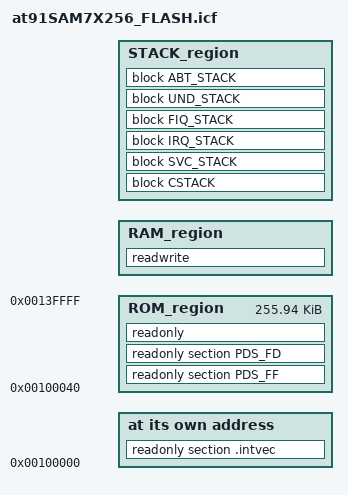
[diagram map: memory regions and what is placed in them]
/*###ICF### Section handled by ICF editor, don't touch! ****/

/*-Sizes-*/
define symbol __ICFEDIT_size_cstack__   = 0x400;
define symbol __ICFEDIT_size_svcstack__ = 0x400;
define symbol __ICFEDIT_size_irqstack__ = 0x400;
define symbol __ICFEDIT_size_fiqstack__ = 0x90;
define symbol __ICFEDIT_size_undstack__ = 0x20;
define symbol __ICFEDIT_size_abtstack__ = 0x20;
define symbol __ICFEDIT_size_stacks__ = __ICFEDIT_size_cstack__ + __ICFEDIT_size_svcstack__ + __ICFEDIT_size_irqstack__
                                      + __ICFEDIT_size_fiqstack__ + __ICFEDIT_size_undstack__ + __ICFEDIT_size_abtstack__;

/*-Memory Regions-*/
define symbol __ICFEDIT_intvec_start__ = 0x00100000;
define symbol __ICFEDIT_region_ROM_start__ = 0x00100040;
define symbol __ICFEDIT_region_ROM_end__   = 0x0013FFFF;
define symbol __ICFEDIT_region_STACK_end__ = 0x0020FFFF;
define symbol __ICFEDIT_region_STACK_start__ = __ICFEDIT_region_STACK_end__ - __ICFEDIT_size_stacks__;
define symbol __ICFEDIT_region_RAM_end__   = __ICFEDIT_region_STACK_start__;
define symbol __ICFEDIT_region_RAM_start__ = 0x00200000;


/*-Specific Memory Regions-*/
define symbol __ICFEDIT_abt_start__ = __ICFEDIT_region_STACK_end__ - __ICFEDIT_size_abtstack__;
define symbol __ICFEDIT_abt_end__   = __ICFEDIT_region_STACK_end__;
define symbol __ICFEDIT_und_start__ = __ICFEDIT_abt_start__ - __ICFEDIT_size_undstack__;
define symbol __ICFEDIT_und_end__   = __ICFEDIT_abt_start__;
define symbol __ICFEDIT_fiq_start__ = __ICFEDIT_und_start__ - __ICFEDIT_size_fiqstack__;
define symbol __ICFEDIT_fiq_end__   = __ICFEDIT_und_start__;
define symbol __ICFEDIT_irq_start__ = __ICFEDIT_fiq_start__ - __ICFEDIT_size_irqstack__;
define symbol __ICFEDIT_irq_end__   = __ICFEDIT_fiq_start__;
define symbol __ICFEDIT_svc_start__ = __ICFEDIT_irq_start__ - __ICFEDIT_size_svcstack__;
define symbol __ICFEDIT_svc_end__   = __ICFEDIT_irq_start__;
define symbol __ICFEDIT_cstack_start__ = __ICFEDIT_svc_start__ - __ICFEDIT_size_cstack__;
define symbol __ICFEDIT_cstack_end__   = __ICFEDIT_svc_start__;


define memory mem with size = 4G;
define region ROM_region = mem:[from __ICFEDIT_region_ROM_start__ to __ICFEDIT_region_ROM_end__];
define region RAM_region = mem:[from __ICFEDIT_region_RAM_start__ to __ICFEDIT_region_RAM_end__];
define region STACK_region = mem:[from __ICFEDIT_region_STACK_start__ to __ICFEDIT_region_STACK_end__];

define block CSTACK    with alignment = 8, size = __ICFEDIT_size_cstack__   { };
define block SVC_STACK with alignment = 8, size = __ICFEDIT_size_svcstack__ { };
define block IRQ_STACK with alignment = 8, size = __ICFEDIT_size_irqstack__ { };
define block FIQ_STACK with alignment = 8, size = __ICFEDIT_size_fiqstack__ { };
define block UND_STACK with alignment = 8, size = __ICFEDIT_size_undstack__ { };
define block ABT_STACK with alignment = 8, size = __ICFEDIT_size_abtstack__ { };

initialize by copy { readwrite };
do not initialize  { section .noinit };

place at address mem:__ICFEDIT_intvec_start__    { readonly section .intvec };

place in ROM_region   { readonly section PDS_FF};    /* Persistent Data Base */
place in ROM_region   { readonly section PDS_FD};    /* Persistent Data Base */
place in ROM_region   { readonly };
place in RAM_region   { readwrite };
                        
place in STACK_region { block CSTACK, block SVC_STACK, block IRQ_STACK, block FIQ_STACK,
                        block UND_STACK, block ABT_STACK };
